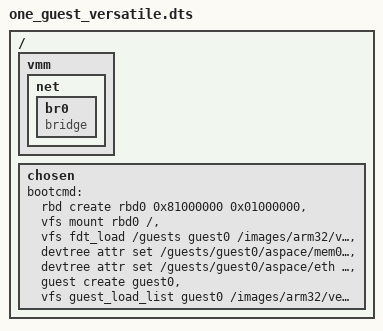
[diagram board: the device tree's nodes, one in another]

/dts-v1/;

/include/ "3dstack.dtsi"

/ {
	vmm {
		net {
			br0 {
				device_type = "netswitch";
				compatible = "bridge";
			};
		};
	};

	chosen {
		bootcmd = /* Create rbd0 device */
			  "rbd create rbd0 0x81000000 0x01000000",

			  /* Mount rbd0 device */
			  "vfs mount rbd0 /",

			  /* Load guest0 device tree from file */
			  "vfs fdt_load /guests guest0 /images/arm32/versatilepb.dtb",

			  /* Update guest0/mem0 region size */
			  "devtree attr set /guests/guest0/aspace/mem0 physical_size physsize 0x02000000",

			  /* Connect guest0/eth netport to br0 */
			  "devtree attr set /guests/guest0/aspace/eth switch string br0",

			  /* Create guest0 */
			  "guest create guest0",

			  /* Load guest0 images */
			  "vfs guest_load_list guest0 /images/arm32/versatilepb/nor_flash.list";
	};
};
